# pse84 register map
Vendor: Infineon Technologies; Series: PSE84; File version: 1.0
CPU: CM33 r0p1, little endian, MPU, FPU, VTOR, 3 interrupt priority bits
Registers are 32-bit, read-write, reset 0x0 unless marked. A register's access mark holds for its fields unless they carry their own. Offsets are from the block's base; [hi:lo] are bit positions; lines under a group give offsets from that group; {n}, {i} and the like mark numbered series; 'fields as' and 'values as' point back to an identical list.

## ICACHE0 — CM33_0/1 CA APB interface
Base 0x42223000
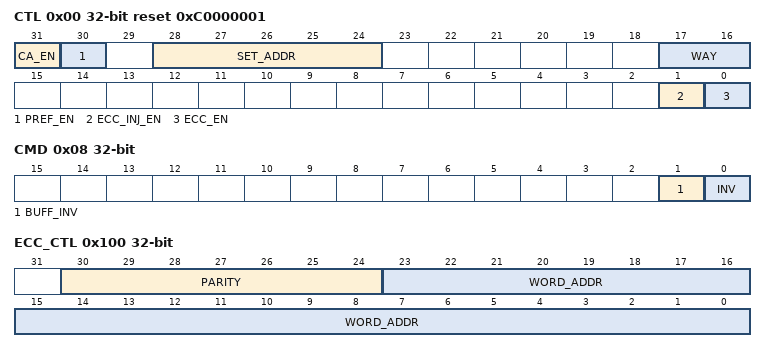
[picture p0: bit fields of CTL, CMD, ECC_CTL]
0x00 CTL reset 0xC0000001 — Cache control
  [31] CA_EN — Cache enable: 0: Disabled. The cache tag valid bits are reset to '0's and the cache LRU information is set to '1's (making way 0 the LRU way and way 3 the MRU way). 1: Enabled.
  [30] PREF_EN — Prefetch enable: 0: Disabled. 1: Enabled. Prefetching requires the cache to be enabled; i.e. ENABLED is '1'.
  [28:24] SET_ADDR — Specifies the cache set for which cache information is provided in STATUS0/1/2.
  [17:16] WAY — Specifies the cache way for which cache information is provided in STATUS0/1/2.
  [1] ECC_INJ_EN — Enable error injection for cache. When '1', the parity (ECC_CTL.PARITY[6:0]) is used when a cache refill is done to the ECC_CTL.WORD_ADDR[23:0] word address.
  [0] ECC_EN — Enable ECC checking for cache accesses: 0: Disabled. 1: Enabled.
0x08 CMD — Cache command
  [1] BUFF_INV — Invalidation of buffers (does not invalidate the caches). SW writes a '1' to clear the buffers. HW sets this field to '0' when the operation is completed.
  [0] INV — Invalidation of cahce and buffer. SW writes a '1' to clear the caches. HW sets this field to '0' when the operation is completed. The caches' LRU structures are also reset to their default state.
0x80 STATUS0 ro — Cache status 0
  [31:0] VALID32 — Sixteen valid bits of the cache line specified by CTL.WAY and CTL.SET_ADDR.
0x84 STATUS1 ro reset not defined — Cache status 1
  [31:0] TAG — Cache line address of the cache line specified by CTL.WAY and CTL.SET_ADDR.
0x88 STATUS2 ro reset 0x3F — Cache status 2
  [5:0] LRU — Six bit LRU representation of the cache set specified by CTL.SET_ADDR. The encoding of the field is as follows ('X_LRU_Y' indicates that way X is Less Recently Used than way Y): Bit 5: 0_LRU_1: way 0 less recently used than way 1. Bit 4: 0_LRU_2. Bit 3: 0_LRU_3. Bit 2: 1_LRU_2. Bit 1: 1_LRU_3. Bit 0: 2_LRU_3.
0x100 ECC_CTL — ECC control
  [30:24] PARITY — ECC parity to use for ECC error injection at address WORD_ADDR. - For cache SRAM ECC, the 7-bit parity PARITY[6:0] is for a 32-bit word.
  [23:0] WORD_ADDR — Specifies the word address where an error will be injected. - On a write transfer to this SRAM address and when the CTL.ECC_INJ_EN bit is '1', the parity (PARITY) is injected.

## CPUSS_SL_CTL — SYSCPUSS Internal slave control registers
Base 0x42298000
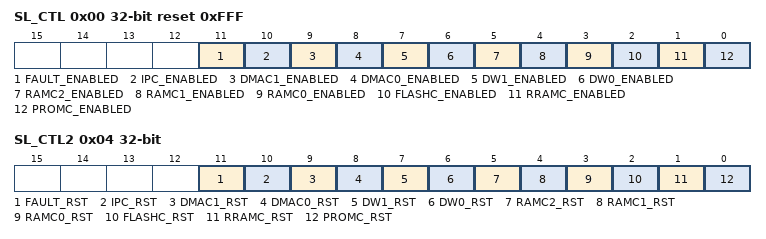
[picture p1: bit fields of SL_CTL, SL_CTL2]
0x00 SL_CTL reset 0xFFF — Slave control (Clock enables)
  [11] FAULT_ENABLED
  [10] IPC_ENABLED
  [9] DMAC1_ENABLED
  [8] DMAC0_ENABLED
  [7] DW1_ENABLED
  [6] DW0_ENABLED
  [5] RAMC2_ENABLED
  [4] RAMC1_ENABLED
  [3] RAMC0_ENABLED
  [2] FLASHC_ENABLED
  [1] RRAMC_ENABLED
  [0] PROMC_ENABLED — Slave enable controls. Each bit indicates whether the respective slave is enabled or not. 0: Disabled 1: Enabled If the slave is disabled, its clock is gated off (constant '0'). Any access (MMIO AHB access or ROM/System SRAM memory access) to slave when disabled result in AHB error response.
0x04 SL_CTL2 — Slave control2 (Reset enables)
  [11] FAULT_RST
  [10] IPC_RST
  [9] DMAC1_RST
  [8] DMAC0_RST
  [7] DW1_RST
  [6] DW0_RST
  [5] RAMC2_RST
  [4] RAMC1_RST
  [3] RAMC0_RST
  [2] FLASHC_RST
  [1] RRAMC_RST
  [0] PROMC_RST — Slave reset controls. Each bit indicates whether the respective slave reset is enabled or not. 0: Disabled 1: Enabled If the slave is under reset enabled state, its clock is gated off (constant '0') and its resets are in activated state (rst_n = 0) Any access (MMIO AHB access or ROM/System SRAM memory access) to slave when disabled result in AHB error response.

## IPC0 — IPC
Base 0x422A0000
Same registers: IPC1 0x441D0000
{0x0+0x20*i} STRUCT[{i}] (i=0..15) group — IPC structure
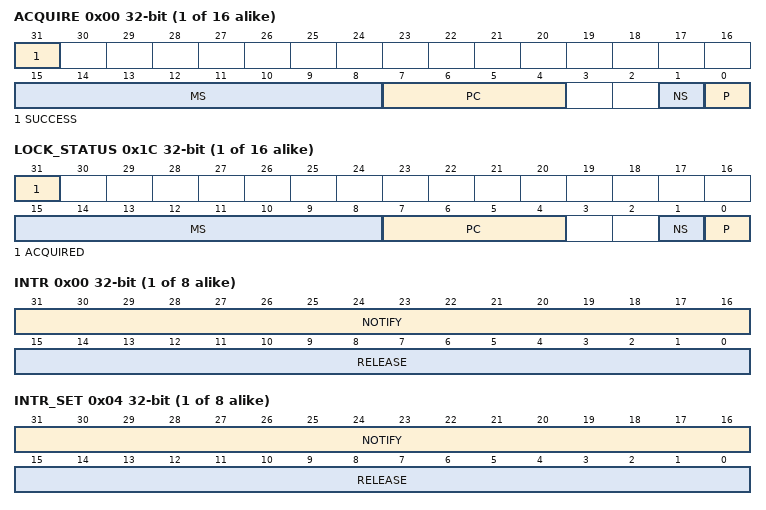
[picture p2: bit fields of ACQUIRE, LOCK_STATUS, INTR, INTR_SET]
  0x00 ACQUIRE ro (reset mask 0x80000000) — IPC acquire
    [31] SUCCESS
    [15:8] MS — This field specifies the bus master identifier that successfully acquired the lock.
    [7:4] PC
    [1] NS
    [0] P
  0x04 RELEASE wo — IPC release
    [15:0] INTR_RELEASE — Writing this field releases a lock and allows for the generation of release events to the IPC interrupt structures, but only when the lock is acquired (LOCK_STATUS.ACQUIRED is '1'). The IPC release cause fields associated with this IPC structure are set to '1', but only for those IPC interrupt structures for which the corresponding bit field in INTR_RELEASE[] is set to '1'. SW writes a '1' to the bit fields to generate a release event. Due to the transient nature of this event, SW always reads a '0' from this field.
  0x08 NOTIFY wo — IPC notification
    [15:0] INTR_NOTIFY — This field allows for the generation of notification events to the IPC interrupt structures. The IPC notification cause fields associated with this IPC structure are set to '1', but only for those IPC interrupt structures for which the corresponding bit field in INTR_NOTIFY[] is set to '1'. SW writes a '1' to the bit fields to generate a notify event. Due to the transient nature of this event, SW always reads a '0' from this field.
  0x0C DATA0 reset not defined — IPC data 0
    [31:0] DATA — This field holds a 32-bit data element that is associated with the IPC structure.
  0x10 DATA1 reset not defined — IPC data 1
    fields as STRUCT[0].DATA0
  0x1C LOCK_STATUS ro (reset mask 0x80000000) — IPC lock status
    [31] ACQUIRED
    [15:8] MS — This field specifies the bus master identifier that successfully acquired the lock.
    [7:4] PC
    [1] NS
    [0] P
{0x1000+0x20*i} INTR_STRUCT[{i}] (i=0..7) group — IPC interrupt structure
  0x00 INTR — Interrupt
    [31:16] NOTIFY — These interrupt cause fields are activated (HW sets the field to '1') when a IPC notification event is detected. One bit field for each master. SW writes a '1' to these field to clear the interrupt cause.
    [15:0] RELEASE — These interrupt cause fields are activated (HW sets the field to '1') when a IPC release event is detected. One bit field for each master. SW writes a '1' to these field to clear the interrupt cause.
  0x04 INTR_SET — Interrupt set
    [31:16] NOTIFY — SW writes a '1' to this field to set the corresponding field in the INTR register.
    [15:0] RELEASE — SW writes a '1' to this field to set the corresponding field in the INTR register.
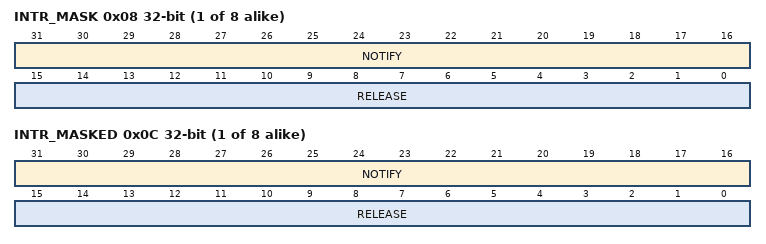
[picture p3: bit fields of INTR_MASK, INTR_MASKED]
  0x08 INTR_MASK — Interrupt mask
    [31:16] NOTIFY — Mask bit for corresponding field in the INTR register.
    [15:0] RELEASE — Mask bit for corresponding field in the INTR register.
  0x0C INTR_MASKED ro — Interrupt masked
    [31:16] NOTIFY — Logical and of corresponding INTR and INTR_MASK fields.
    [15:0] RELEASE — Logical and of corresponding request and mask bits.
